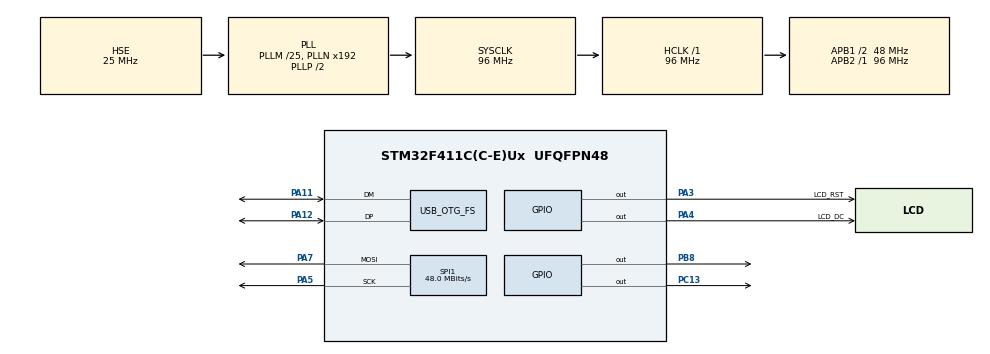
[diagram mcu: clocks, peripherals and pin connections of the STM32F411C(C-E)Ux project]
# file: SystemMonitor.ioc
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Dma.Request0=SPI1_TX
Dma.SPI1_TX.0.Direction=DMA_MEMORY_TO_PERIPH
Dma.SPI1_TX.0.FIFOMode=DMA_FIFOMODE_DISABLE
Dma.SPI1_TX.0.Instance=DMA2_Stream2
Dma.SPI1_TX.0.MemDataAlignment=DMA_MDATAALIGN_BYTE
Dma.SPI1_TX.0.MemInc=DMA_MINC_ENABLE
Dma.SPI1_TX.0.Mode=DMA_NORMAL
Dma.SPI1_TX.0.PeriphDataAlignment=DMA_PDATAALIGN_BYTE
Dma.SPI1_TX.0.PeriphInc=DMA_PINC_DISABLE
Dma.SPI1_TX.0.Priority=DMA_PRIORITY_MEDIUM
FREERTOS.Tasks01=defaultTask,24,1024,StartDefaultTask,Default,NULL,Dynamic,NULL,NULL;uiTask,24,2048,StartuiTask02,Default,NULL,Dynamic,NULL,NULL
FREERTOS.configCHECK_FOR_STACK_OVERFLOW=1
FREERTOS.configENABLE_FPU=1
FREERTOS.configTOTAL_HEAP_SIZE=15360
FREERTOS.configUSE_NEWLIB_REENTRANT=1
Mcu.Family=STM32F4
Mcu.Name=STM32F411C(C-E)Ux
Mcu.Package=UFQFPN48
NVIC.DMA2_Stream2_IRQn=true\:5\:0\:false\:false\:true\:true\:false\:true\:true
NVIC.OTG_FS_IRQn=true\:5\:0\:false\:false\:true\:true\:false\:true\:true
NVIC.PriorityGroup=NVIC_PRIORITYGROUP_4
NVIC.TIM1_UP_TIM10_IRQn=true\:15\:0\:false\:false\:true\:false\:false\:true\:true
NVIC.TimeBase=TIM1_UP_TIM10_IRQn
NVIC.TimeBaseIP=TIM1
PA11.Mode=Device_Only
PA11.Signal=USB_OTG_FS_DM
PA12.Mode=Device_Only
PA12.Signal=USB_OTG_FS_DP
PA13.Mode=Trace_Asynchronous_SW
PA13.Signal=SYS_JTMS-SWDIO
PA14.Mode=Trace_Asynchronous_SW
PA14.Signal=SYS_JTCK-SWCLK
PA3.GPIO_Label=LCD_RST
PA3.Signal=GPIO_Output
PA4.GPIO_Label=LCD_DC
PA4.Signal=GPIO_Output
PA5.Mode=TX_Only_Simplex_Unidirect_Master
PA5.Signal=SPI1_SCK
PA7.Mode=TX_Only_Simplex_Unidirect_Master
PA7.Signal=SPI1_MOSI
PB3.Mode=Trace_Asynchronous_SW
PB3.Signal=SYS_JTDO-SWO
PB8.Signal=GPIO_Output
PC13-ANTI_TAMP.Signal=GPIO_Output
PH0\ -\ OSC_IN.Mode=HSE-External-Oscillator
PH0\ -\ OSC_IN.Signal=RCC_OSC_IN
PH1\ -\ OSC_OUT.Mode=HSE-External-Oscillator
PH1\ -\ OSC_OUT.Signal=RCC_OSC_OUT
ProjectManager.HeapSize=0x200
ProjectManager.StackSize=0x400
ProjectManager.TargetToolchain=STM32CubeIDE
RCC.48MHZClocksFreq_Value=48000000
RCC.AHBFreq_Value=96000000
RCC.APB1CLKDivider=RCC_HCLK_DIV2
RCC.APB1Freq_Value=48000000
RCC.APB1TimFreq_Value=96000000
RCC.APB2Freq_Value=96000000
RCC.APB2TimFreq_Value=96000000
RCC.CortexFreq_Value=96000000
RCC.HCLKFreq_Value=96000000
RCC.HSE_VALUE=25000000
RCC.HSI_VALUE=16000000
RCC.LSE_VALUE=32768
RCC.PLLM=25
RCC.SYSCLKFreq_VALUE=96000000
RCC.SYSCLKSource=RCC_SYSCLKSOURCE_PLLCLK
RCC.VCOOutputFreq_Value=192000000
SPI1.BaudRatePrescaler=SPI_BAUDRATEPRESCALER_2
SPI1.CLKPolarity=SPI_POLARITY_HIGH
SPI1.CalculateBaudRate=48.0 MBits/s
SPI1.Direction=SPI_DIRECTION_2LINES
SPI1.Mode=SPI_MODE_MASTER
SPI1.VirtualType=VM_MASTER
USB_DEVICE.CLASS_NAME_FS=CDC
USB_DEVICE.PRODUCT_STRING_CDC_FS=STM32 System Monitor
USB_DEVICE.VirtualMode=Cdc
USB_DEVICE.VirtualModeFS=Cdc_FS
USB_OTG_FS.VirtualMode=Device_Only
VP_FREERTOS_VS_CMSIS_V2.Mode=CMSIS_V2
VP_SYS_VS_tim1.Mode=TIM1
VP_USB_DEVICE_VS_USB_DEVICE_CDC_FS.Mode=CDC_FS
board=custom

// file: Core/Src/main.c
/* USER CODE BEGIN Header */
/**
  ******************************************************************************
  * @file           : main.c
  * @brief          : Main program body
  ******************************************************************************
  * @attention
  *
  * Copyright (c) 2022 STMicroelectronics.
  * All rights reserved.
  *
  * This software is licensed under terms that can be found in the LICENSE file
  * in the root directory of this software component.
  * If no LICENSE file comes with this software, it is provided AS-IS.
  *
  ******************************************************************************
  */
/* USER CODE END Header */
#include "main.h"
#include "cmsis_os.h"
#include "usb_device.h"

/* USER CODE BEGIN Includes */
#include "lvgl.h"
#include "app_ui.h"
/* USER CODE END Includes */

SPI_HandleTypeDef hspi1;
DMA_HandleTypeDef hdma_spi1_tx;

/* Definitions for defaultTask */
osThreadId_t defaultTaskHandle;
const osThreadAttr_t defaultTask_attributes = {
  .name = "defaultTask",
  .stack_size = 1024 * 4,
  .priority = (osPriority_t) osPriorityNormal,
};
/* Definitions for uiTask */
osThreadId_t uiTaskHandle;
const osThreadAttr_t uiTask_attributes = {
  .name = "uiTask",
  .stack_size = 2048 * 4,
  .priority = (osPriority_t) osPriorityNormal,
};

void SystemClock_Config(void);
static void MX_GPIO_Init(void);
static void MX_DMA_Init(void);
static void MX_SPI1_Init(void);
void StartDefaultTask(void *argument);
void StartuiTask02(void *argument);

int main(void)
{

  /* MCU Configuration--------------------------------------------------------*/

  /* Reset of all peripherals, Initializes the Flash interface and the Systick. */
  HAL_Init();

  /* Configure the system clock */
  SystemClock_Config();

  /* Initialize all configured peripherals */
  MX_GPIO_Init();
  MX_DMA_Init();
  MX_SPI1_Init();

  /* Init scheduler */
  osKernelInitialize();

  /* Create the thread(s) */
  /* creation of defaultTask */
  defaultTaskHandle = osThreadNew(StartDefaultTask, NULL, &defaultTask_attributes);

  /* creation of uiTask */
  uiTaskHandle = osThreadNew(StartuiTask02, NULL, &uiTask_attributes);

  /* Start scheduler */
  osKernelStart();

  /* We should never get here as control is now taken by the scheduler */
  /* Infinite loop */
  while (1)
  {

  }
}

void SystemClock_Config(void)
{
  RCC_OscInitTypeDef RCC_OscInitStruct = {0};
  RCC_ClkInitTypeDef RCC_ClkInitStruct = {0};

  /** Configure the main internal regulator output voltage
  */
  __HAL_RCC_PWR_CLK_ENABLE();
  __HAL_PWR_VOLTAGESCALING_CONFIG(PWR_REGULATOR_VOLTAGE_SCALE1);

  /** Initializes the RCC Oscillators according to the specified parameters
  * in the RCC_OscInitTypeDef structure.
  */
  RCC_OscInitStruct.OscillatorType = RCC_OSCILLATORTYPE_HSE;
  RCC_OscInitStruct.HSEState = RCC_HSE_ON;
  RCC_OscInitStruct.PLL.PLLState = RCC_PLL_ON;
  RCC_OscInitStruct.PLL.PLLSource = RCC_PLLSOURCE_HSE;
  RCC_OscInitStruct.PLL.PLLM = 25;
  RCC_OscInitStruct.PLL.PLLN = 192;
  RCC_OscInitStruct.PLL.PLLP = RCC_PLLP_DIV2;
  RCC_OscInitStruct.PLL.PLLQ = 4;
  if (HAL_RCC_OscConfig(&RCC_OscInitStruct) != HAL_OK)
  {
    Error_Handler();
  }

  /** Initializes the CPU, AHB and APB buses clocks
  */
  RCC_ClkInitStruct.ClockType = RCC_CLOCKTYPE_HCLK|RCC_CLOCKTYPE_SYSCLK
                              |RCC_CLOCKTYPE_PCLK1|RCC_CLOCKTYPE_PCLK2;
  RCC_ClkInitStruct.SYSCLKSource = RCC_SYSCLKSOURCE_PLLCLK;
  RCC_ClkInitStruct.AHBCLKDivider = RCC_SYSCLK_DIV1;
  RCC_ClkInitStruct.APB1CLKDivider = RCC_HCLK_DIV2;
  RCC_ClkInitStruct.APB2CLKDivider = RCC_HCLK_DIV1;

  if (HAL_RCC_ClockConfig(&RCC_ClkInitStruct, FLASH_LATENCY_3) != HAL_OK)
  {
    Error_Handler();
  }
}

static void MX_SPI1_Init(void)
{

  /* SPI1 parameter configuration*/
  hspi1.Instance = SPI1;
  hspi1.Init.Mode = SPI_MODE_MASTER;
  hspi1.Init.Direction = SPI_DIRECTION_2LINES;
  hspi1.Init.DataSize = SPI_DATASIZE_8BIT;
  hspi1.Init.CLKPolarity = SPI_POLARITY_HIGH;
  hspi1.Init.CLKPhase = SPI_PHASE_1EDGE;
  hspi1.Init.NSS = SPI_NSS_SOFT;
  hspi1.Init.BaudRatePrescaler = SPI_BAUDRATEPRESCALER_2;
  hspi1.Init.FirstBit = SPI_FIRSTBIT_MSB;
  hspi1.Init.TIMode = SPI_TIMODE_DISABLE;
  hspi1.Init.CRCCalculation = SPI_CRCCALCULATION_DISABLE;
  hspi1.Init.CRCPolynomial = 10;
  if (HAL_SPI_Init(&hspi1) != HAL_OK)
  {
    Error_Handler();
  }

}

static void MX_DMA_Init(void)
{

  /* DMA controller clock enable */
  __HAL_RCC_DMA2_CLK_ENABLE();

  /* DMA interrupt init */
  /* DMA2_Stream2_IRQn interrupt configuration */
  HAL_NVIC_SetPriority(DMA2_Stream2_IRQn, 5, 0);
  HAL_NVIC_EnableIRQ(DMA2_Stream2_IRQn);

}

static void MX_GPIO_Init(void)
{
  GPIO_InitTypeDef GPIO_InitStruct = {0};

  /* GPIO Ports Clock Enable */
  __HAL_RCC_GPIOC_CLK_ENABLE();
  __HAL_RCC_GPIOH_CLK_ENABLE();
  __HAL_RCC_GPIOA_CLK_ENABLE();
  __HAL_RCC_GPIOB_CLK_ENABLE();

  /*Configure GPIO pin Output Level */
  HAL_GPIO_WritePin(GPIOC, GPIO_PIN_13, GPIO_PIN_RESET);

  /*Configure GPIO pin Output Level */
  HAL_GPIO_WritePin(GPIOA, LCD_RST_Pin|LCD_DC_Pin, GPIO_PIN_RESET);

  /*Configure GPIO pin Output Level */
  HAL_GPIO_WritePin(GPIOB, GPIO_PIN_8, GPIO_PIN_RESET);

  /*Configure GPIO pin : PC13 */
  GPIO_InitStruct.Pin = GPIO_PIN_13;
  GPIO_InitStruct.Mode = GPIO_MODE_OUTPUT_PP;
  GPIO_InitStruct.Pull = GPIO_NOPULL;
  GPIO_InitStruct.Speed = GPIO_SPEED_FREQ_LOW;
  HAL_GPIO_Init(GPIOC, &GPIO_InitStruct);

  /*Configure GPIO pins : LCD_RST_Pin LCD_DC_Pin */
  GPIO_InitStruct.Pin = LCD_RST_Pin|LCD_DC_Pin;
  GPIO_InitStruct.Mode = GPIO_MODE_OUTPUT_PP;
  GPIO_InitStruct.Pull = GPIO_NOPULL;
  GPIO_InitStruct.Speed = GPIO_SPEED_FREQ_LOW;
  HAL_GPIO_Init(GPIOA, &GPIO_InitStruct);

  /*Configure GPIO pin : PB8 */
  GPIO_InitStruct.Pin = GPIO_PIN_8;
  GPIO_InitStruct.Mode = GPIO_MODE_OUTPUT_PP;
  GPIO_InitStruct.Pull = GPIO_NOPULL;
  GPIO_InitStruct.Speed = GPIO_SPEED_FREQ_LOW;
  HAL_GPIO_Init(GPIOB, &GPIO_InitStruct);

}

void StartDefaultTask(void *argument)
{
  /* init code for USB_DEVICE */
  MX_USB_DEVICE_Init();
  /* USER CODE BEGIN 5 */

  /* Infinite loop */
  for(;;)
  {
    osDelay(1000);
    HAL_GPIO_TogglePin(GPIOC, GPIO_PIN_13);

  }
  /* USER CODE END 5 */
}

void StartuiTask02(void *argument)
{
  /* USER CODE BEGIN StartuiTask02 */
  /* Infinite loop */
  for(;;)
  {
    ui_task();
  }
  /* USER CODE END StartuiTask02 */
}

void HAL_TIM_PeriodElapsedCallback(TIM_HandleTypeDef *htim)
{
  if (htim->Instance == TIM1) {
    HAL_IncTick();
  }
  /* USER CODE BEGIN Callback 1 */
  if (htim->Instance == TIM1) {
    lv_tick_inc(1);

  }
  /* USER CODE END Callback 1 */
}

void Error_Handler(void)
{
  __disable_irq();
  while (1)
  {
  }
}

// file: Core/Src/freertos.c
/* USER CODE BEGIN Header */
/**
  ******************************************************************************
  * File Name          : freertos.c
  * Description        : Code for freertos applications
  ******************************************************************************
  * @attention
  *
  * Copyright (c) 2022 STMicroelectronics.
  * All rights reserved.
  *
  * This software is licensed under terms that can be found in the LICENSE file
  * in the root directory of this software component.
  * If no LICENSE file comes with this software, it is provided AS-IS.
  *
  ******************************************************************************
  */
/* USER CODE END Header */

#include "FreeRTOS.h"
#include "task.h"
#include "main.h"

/* Hook prototypes */
void vApplicationStackOverflowHook(xTaskHandle xTask, signed char *pcTaskName);

/* USER CODE BEGIN 4 */
void vApplicationStackOverflowHook(xTaskHandle xTask, signed char *pcTaskName)
{
   /* Run time stack overflow checking is performed if
   configCHECK_FOR_STACK_OVERFLOW is defined to 1 or 2. This hook function is
   called if a stack overflow is detected. */
	while(1)
	{}
}
/* USER CODE END 4 */
